# S32K142 register map
Vendor: NXP; Series: S32K; File version: 1.6
CPU: CM4 r0p1, little endian, MPU, FPU, 4 interrupt priority bits
Registers are 32-bit, read-write, reset 0x0 unless marked. A register's access mark holds for its fields unless they carry their own. Offsets are from the block's base; [hi:lo] are bit positions; {n}, {i} and the like mark numbered series.

## ADC0 — Analog-to-Digital Converter
Base 0x4003B000; register names take the prefix ADC0_
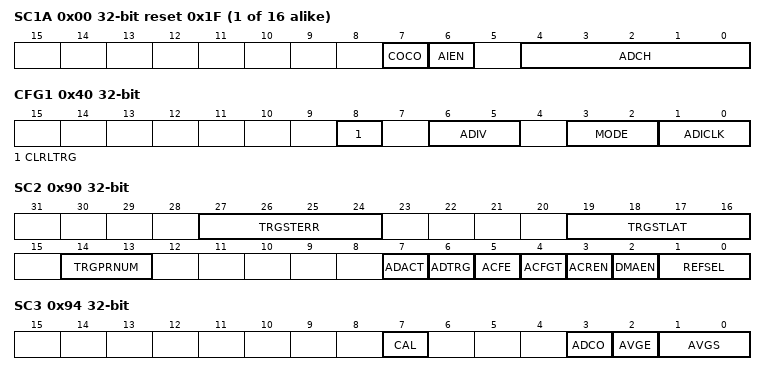
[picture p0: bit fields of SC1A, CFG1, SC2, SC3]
0x00 SC1{x} (x=A,B,C,D,E,F,G,H,I,J,K,L,M,N,O,P; step 0x4) reset 0x1F — ADC Status and Control Register 1
  [7] COCO ro — Conversion Complete Flag
    0=Conversion is not completed; 1=Conversion is completed
  [6] AIEN — Interrupt Enable
    0=Conversion complete interrupt is disabled; 1=Conversion complete interrupt is enabled
  [4:0] ADCH — Input channel select
    {v}=Exernal channel {v} is selected as input (v=0..15); 18=Exernal channel 18 is selected as input; 19=Exernal channel 19 is selected as input; 21=Internal channel 0 is selected as input; 22=Internal channel 1 is selected as input; 23=Internal channel 2 is selected as input; 26=Temp Sensor; 27=Band Gap; 28=Internal channel 3 is selected as input; 29=VREFSH is selected as input. Voltage reference selected is determined by SC2[REFSEL].; 30=VREFSL is selected as input. Voltage reference selected is determined by SC2[REFSEL].; 31=Module is disabled
0x40 CFG1 — ADC Configuration Register 1
  [8] CLRLTRG wo — Clear Latch Trigger in Trigger Handler Block
  [6:5] ADIV — Clock Divide Select
    0=The divide ratio is 1 and the clock rate is input clock; 1=The divide ratio is 2 and the clock rate is (input clock)/2; 2=The divide ratio is 4 and the clock rate is (input clock)/4; 3=The divide ratio is 8 and the clock rate is (input clock)/8
  [3:2] MODE — Conversion mode selection
    0=8-bit conversion; 1=12-bit conversion; 2=10-bit conversion
  [1:0] ADICLK — Input Clock Select
    {v}=Alternate clock {v+1} (ADC_ALTCLK{v+1}) (v=0..3)
0x44 CFG2 reset 0xC — ADC Configuration Register 2
  [7:0] SMPLTS — Sample Time Select
0x48 R{x} (x=A,B,C,D,E,F,G,H,I,J,K,L,M,N,O,P; step 0x4) ro — ADC Data Result Registers
  [11:0] D — Data result
{0x84+4i} CV{i} (i=1..2) — Compare Value Registers
  [15:0] CV — Compare Value.
0x90 SC2 — Status and Control Register 2
  [27:24] TRGSTERR ro — Error in Multiplexed Trigger Request
    0=No error has occurred; 1=An error has occurred
  [19:16] TRGSTLAT ro — Trigger Status
    0=No trigger request has been latched; 1=A trigger request has been latched
  [14:13] TRGPRNUM ro — Trigger Process Number
  [7] ADACT ro — Conversion Active
    0=Conversion not in progress; 1=Conversion in progress
  [6] ADTRG — Conversion Trigger Select
    0=Software trigger selected; 1=Hardware trigger selected
  [5] ACFE — Compare Function Enable
    0=Compare function disabled; 1=Compare function enabled
  [4] ACFGT — Compare Function Greater Than Enable
  [3] ACREN — Compare Function Range Enable
  [2] DMAEN — DMA Enable
    0=DMA is disabled; 1=DMA is enabled and will assert the ADC DMA request during an ADC conversion complete event , which is indicated when any SC1n[COCO] flag is asserted
  [1:0] REFSEL — Voltage Reference Selection
    0=Default voltage reference pin pair, that is, external pins VREFH and VREFL; 1=Alternate reference voltage, that is, VALTH. This voltage may be additional external pin or internal source depending on the MCU configuration. See the chip configuration information for details specific to this MCU.
0x94 SC3 — Status and Control Register 3
  [7] CAL — Calibration
  [3] ADCO — Continuous Conversion Enable
    0=One conversion will be performed (or one set of conversions, if AVGE is set) after a conversion is initiated; 1=Continuous conversions will be performed (or continuous sets of conversions, if AVGE is set) after a conversion is initiated
  [2] AVGE — Hardware Average Enable
    0=Hardware average function disabled; 1=Hardware average function enabled
  [1:0] AVGS — Hardware Average Select
    0=4 samples averaged; 1=8 samples averaged; 2=16 samples averaged; 3=32 samples averaged
0x98 BASE_OFS reset 0x40 — BASE Offset Register
  [7:0] BA_OFS — Base Offset Error Correction Value
0x9C OFS — ADC Offset Correction Register
  [15:0] OFS — Offset Error Correction Value
0xA0 USR_OFS — USER Offset Correction Register
  [7:0] USR_OFS — USER Offset Error Correction Value
0xA4 XOFS reset 0x30 — ADC X Offset Correction Register
  [5:0] XOFS — X offset error correction value
0xA8 YOFS reset 0x37 — ADC Y Offset Correction Register
  [7:0] YOFS — Y offset error correction value
0xAC G reset 0x2F0 — ADC Gain Register
  [10:0] G — Gain error adjustment factor for the overall conversion
0xB0 UG reset 0x4 — ADC User Gain Register
  [9:0] UG — User gain error correction value
0xB4 CLPS reset 0x2E — ADC General Calibration Value Register S
  [6:0] CLPS — Calibration Value
0xB8 CLP3 reset 0x180 — ADC Plus-Side General Calibration Value Register 3
  [9:0] CLP3 — Calibration Value
0xBC CLP2 reset 0xB8 — ADC Plus-Side General Calibration Value Register 2
  [9:0] CLP2 — Calibration Value
0xC0 CLP1 reset 0x5C — ADC Plus-Side General Calibration Value Register 1
  [8:0] CLP1 — Calibration Value
0xC4 CLP0 reset 0x2E — ADC Plus-Side General Calibration Value Register 0
  [7:0] CLP0 — Calibration Value
0xC8 CLPX — ADC Plus-Side General Calibration Value Register X
  [6:0] CLPX — Calibration Value
0xCC CLP9 — ADC Plus-Side General Calibration Value Register 9
  [6:0] CLP9 — Calibration Value
0xD0 CLPS_OFS — ADC General Calibration Offset Value Register S
  [3:0] CLPS_OFS — CLPS Offset
0xD4 CLP3_OFS — ADC Plus-Side General Calibration Offset Value Register 3
  [3:0] CLP3_OFS — CLP3 Offset
0xD8 CLP2_OFS — ADC Plus-Side General Calibration Offset Value Register 2
  [3:0] CLP2_OFS — CLP2 Offset
0xDC CLP1_OFS — ADC Plus-Side General Calibration Offset Value Register 1
  [3:0] CLP1_OFS — CLP1 Offset
0xE0 CLP0_OFS — ADC Plus-Side General Calibration Offset Value Register 0
  [3:0] CLP0_OFS — CLP0 Offset
0xE4 CLPX_OFS reset 0x440 — ADC Plus-Side General Calibration Offset Value Register X
  [11:0] CLPX_OFS — CLPX Offset
0xE8 CLP9_OFS reset 0x240 — ADC Plus-Side General Calibration Offset Value Register 9
  [11:0] CLP9_OFS — CLP9 Offset

## ADC1 — Analog-to-Digital Converter
Base 0x40027000; register names take the prefix ADC1_
Registers as ADC0.

## Notices in the file
Redistribution and use in source and binary forms, with or without modification,
are permitted provided that the following conditions are met:
o Redistributions of source code must retain the above copyright notice, this list
of conditions and the following disclaimer.
o Redistributions in binary form must reproduce the above copyright notice, this
list of conditions and the following disclaimer in the documentation and/or
other materials provided with the distribution.
o Neither the name of Freescale Semiconductor, Inc. nor the names of its
contributors may be used to endorse or promote products derived from this
software without specific prior written permission.
THIS SOFTWARE IS PROVIDED BY THE COPYRIGHT HOLDERS AND CONTRIBUTORS "AS IS" AND
ANY EXPRESS OR IMPLIED WARRANTIES, INCLUDING, BUT NOT LIMITED TO, THE IMPLIED
WARRANTIES OF MERCHANTABILITY AND FITNESS FOR A PARTICULAR PURPOSE ARE
DISCLAIMED. IN NO EVENT SHALL THE COPYRIGHT HOLDER OR CONTRIBUTORS BE LIABLE FOR
ANY DIRECT, INDIRECT, INCIDENTAL, SPECIAL, EXEMPLARY, OR CONSEQUENTIAL DAMAGES
(INCLUDING, BUT NOT LIMITED TO, PROCUREMENT OF SUBSTITUTE GOODS OR SERVICES;
LOSS OF USE, DATA, OR PROFITS; OR BUSINESS INTERRUPTION) HOWEVER CAUSED AND ON
ANY THEORY OF LIABILITY, WHETHER IN CONTRACT, STRICT LIABILITY, OR TORT
(INCLUDING NEGLIGENCE OR OTHERWISE) ARISING IN ANY WAY OUT OF THE USE OF THIS
SOFTWARE, EVEN IF ADVISED OF THE POSSIBILITY OF SUCH DAMAGE.
